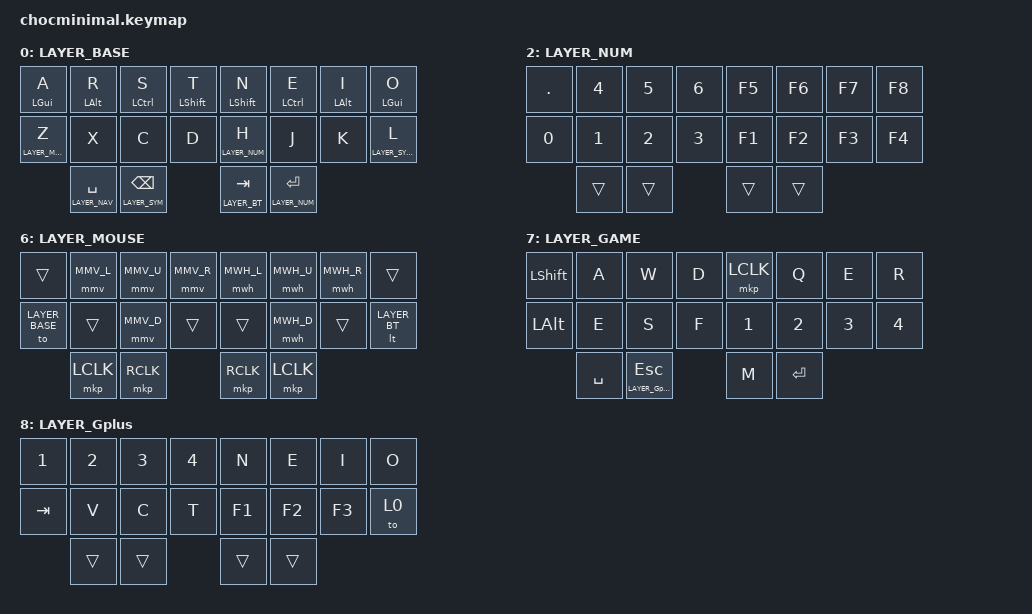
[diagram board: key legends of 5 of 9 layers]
#include <behaviors.dtsi>
#include <dt-bindings/zmk/bt.h>
#include <dt-bindings/zmk/keys.h>
#include <dt-bindings/zmk/outputs.h>
#include <dt-bindings/zmk/mouse.h>
// LAYERS

#define LAYER_BASE  0
#define LAYER_NAV   1
#define LAYER_NUM   2
#define LAYER_SYM   3
#define LAYER_SYM2  4
#define LAYER_BT    5
#define LAYER_MOUSE 6
#define LAYER_GAME  7
#define LAYER_Gplus 8


// MOUSE MOVE SETTINGS
#define MMV_U MOVE_VERT(-1600)
#define MMV_D MOVE_VERT(1600)
#define MMV_L MOVE_HOR(-1600)
#define MMV_R MOVE_HOR(1600)

&mmv {
    time-to-max-speed-ms = <500>;
    acceleration-exponent = <1>;
};

// MOUSE SCROLL SETTINGS
#define MWH_U SCROLL_VERT(65)
#define MWH_D SCROLL_VERT(-65)
#define MWH_L SCROLL_HOR(-65)
#define MWH_R SCROLL_HOR(65)

&mwh {
    time-to-max-speed-ms = <2000>;
    acceleration-exponent = <0>;
};

// MACROS
// CONFIGRATION
#define COMBO(NAME, LAYER, TIMEOUT, KEYPOS) \
    combo_##NAME { \
        layers = <LAYER>; \
        timeout-ms = <TIMEOUT>; \
        key-positions = <KEYPOS>; \
        bindings = <&kp NAME>; \
    };

&lt {
    flavor = "tap-preferred";
    tapping-term-ms = <200>;
    quick-tap-ms = <0>;
};

// define timeout for some functions
//#if !defined TIMEOUT_COMBO_2
//#define TIMEOUT_COMBO_2 175
//#endif
//#if !defined TIMEOUT_COMBO_3
//#define TIMEOUT_COMBO_3 200
//#endif
//#if !defined TIMEOUT_LAYER_HOLD
//#define TIMEOUT_LAYER_HOLD 200
//#endif
// homerow and combos

/ {
    behaviors {
        hm: homerow_mods {
            compatible = "zmk,behavior-hold-tap";
            label = "homerow_mods";
            #binding-cells = <2>;
            tapping-term-ms = <250>;
            quick_tap_ms = <0>;
            flavor = "tap-preferred";
            bindings = <&kp>, <&kp>;
        };
    };

    combos {
        compatible = "zmk,combos";

        COMBO(Q, 0, 55, 0 8)
        COMBO(W, 0, 55, 1 9)
        COMBO(F, 0, 55, 1 2)
        COMBO(P, 0, 55, 2 3)
        COMBO(ESC, 0, 50, 8 9)
        COMBO(B, 0, 55, 2 10)
        COMBO(G, 0, 50, 3 11)
        COMBO(V, 0, 60, 10 11)
        COMBO(COMMA, 0, 50, 4 6) 
        COMBO(DOT, 0, 50, 4 5)
        COMBO(U, 0, 50, 4 12)
        COMBO(Y, 0, 60, 6 14)
        COMBO(MINUS, 0, 50, 10 11)
        COMBO(M, 0, 50, 7 15)
        COMBO(FSLH, 0, 35, 5 12)
        COMBO(CAPS, 0, 50, 14 15)
        COMBO(DEL, 0, 50, 5 6)
        COMBO(ENTER, 0, 50, 12 13)
        COMBO(TAB, 0, 50, 16 17)
        COMBO(F9, 2, 50, 6 7)
        COMBO(F10, 2, 50, 12 13)
        COMBO(F11, 2, 50, 13 14)
        COMBO(F12, 2, 50, 14 15)
        COMBO(N7, 2, 50, 1 9)
        COMBO(N8, 2, 50, 1 3)
        COMBO(N9, 2, 50, 3 11)
        COMBO(LBKT, 3, 50, 9 10)
        COMBO(RBKT, 3, 50, 13 14)
        COMBO(LBRC, 3, 50, 3 11)
        COMBO(RBRC, 3, 50, 4 12)
        COMBO(LPAR, 3, 50, 2 3)
        COMBO(RPAR, 3, 50, 4 5)
    };

    keymap {
        compatible = "zmk,keymap";

        base_layer {
            label = "LAYER_BASE";
            bindings = <
                                                                       
&hm LGUI A         &hm LALT R  &hm LCTRL S   &hm LSHIFT T          &hm LSHIFT N      &hm LCTRL E &hm LALT I  &hm LGUI O
&lt LAYER_MOUSE Z  &kp X       &kp C         &kp D                 &lt LAYER_NUM H   &kp J       &kp K       &lt LAYER_SYM2 L
                   &lt LAYER_NAV SPACE  &lt LAYER_SYM BACKSPACE    &lt LAYER_BT TAB  &lt LAYER_NUM ENTER
            >;

            //trackball-bindings = <&tmv_coarse>;
        };

        nav_layer {
            label = "LAYER_NAV";
            bindings = <
                                                            
&trans    &mkp RCLK  &mkp MCLK &mkp LCLK             &kp LEFT        &kp DOWN  &kp UP    &kp RIGHT
&kp L     &kp K      &kp J     &kp H                 &kp LC(HOME)    &kp HOME  &kp END   &kp LC(END)
                     &trans    &trans       &trans   &trans    &trans
            >;
        };

        number_layer {
            label = "LAYER_NUM";
            bindings = <
                                           
&kp DOT  &kp N4  &kp N5  &kp N6          &kp F5   &kp F6    &kp F7      &kp F8
&kp N0   &kp N1  &kp N2  &kp N3          &kp F1   &kp F2    &kp F3      &kp F4
                 &trans  &trans          &trans  &trans
            >;
        };

        symbol_layer {
            label = "LAYER_SYM";
            bindings = <
                                                     
&kp EXCL   &kp AT     &kp HASH  &kp DLLR            &kp AMPS  &kp STAR  &kp DQT   &kp SQT
&kp UNDER  &kp EQUAL  &kp PLUS  &kp PRCNT           &kp BSLH  &kp PIPE  &kp SEMI  &kp COLON
                      &trans    &trans     &trans   &trans    &trans
            >;
        };

        symbol2_layer {
            label = "LAYER_SYM2";
            bindings = <
                                                                
&kp GRAVE     &trans &trans  &kp INT5            &kp INT4  &trans          &trans            &trans
&kp LS(INT1)  &trans &trans  &trans              &kp INT3  &kp LESS_THAN   &kp GREATER_THAN  &trans
                     &trans  &trans    &trans   &mkp MCLK  &mkp LCLK
            >;
        };

        bt_layer {
            label = "LAYER_BT";
            bindings = <
                                                                              
&bt BT_CLR  &bt BT_SEL 3  &bt BT_SEL 2  &bt BT_SEL 1             &bt BT_SEL 1  &bt BT_SEL 2  &bt BT_SEL 3  
&trans      &trans        &trans        &to LAYER_GAME           &trans        &trans        &trans        &bt BT_CLR
                          &mkp LCLK     &mkp RCLK                &mkp RCLK  &mkp LCLK
            >;
            //trackball-bindings = <&tsl_fine>;
        };

        mouse_layer {
            label = "LAYER_MOUSE";
            bindings = <
&trans          &mmv MMV_L  &mmv MMV_U  &mmv MMV_R      &mwh MWH_L  &mwh MWH_U  &mwh MWH_R   &trans
&to LAYER_BASE  &trans      &mmv MMV_D  &trans          &trans      &mwh MWH_D  &trans       &lt LAYER_BT
                            &mkp LCLK   &mkp RCLK                &mkp RCLK  &mkp LCLK
            >;
        };

        game_layer {
            label = "LAYER_GAME";
            bindings = <
                                                      
&kp LSHFT  &kp A  &kp W      &kp D                     &mkp LCLK   &kp Q   &kp E   &kp R
&kp LALT   &kp E  &kp S      &kp F                     &kp N1      &kp N2  &kp N3  &kp N4
                  &kp SPACE  &lt LAYER_Gplus ESC       &kp M   &kp ENTER
            >;
        };

        game+_layer {
            label = "LAYER_Gplus";
            bindings = <
                                       
&kp N1   &kp N2  &kp N3  &kp N4             &kp N   &kp E   &kp I   &kp O
&kp TAB  &kp V   &kp C   &kp T              &kp F1  &kp F2  &kp F3  &to 0
                 &trans  &trans             &trans  &trans
            >;
        };
    };
};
